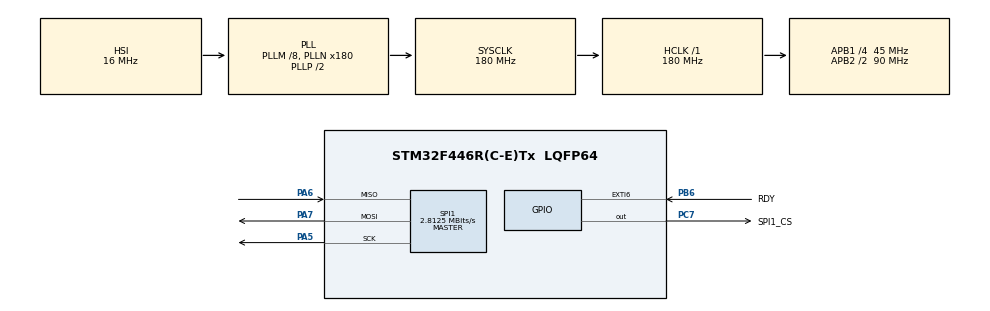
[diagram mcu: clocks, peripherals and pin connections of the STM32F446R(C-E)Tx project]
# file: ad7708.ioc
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Mcu.Family=STM32F4
Mcu.Name=STM32F446R(C-E)Tx
Mcu.Package=LQFP64
NVIC.PriorityGroup=NVIC_PRIORITYGROUP_4
PA13.Mode=Serial_Wire
PA13.Signal=SYS_JTMS-SWDIO
PA14.Mode=Serial_Wire
PA14.Signal=SYS_JTCK-SWCLK
PA5.Mode=Full_Duplex_Master
PA5.Signal=SPI1_SCK
PA6.Mode=Full_Duplex_Master
PA6.Signal=SPI1_MISO
PA7.Mode=Full_Duplex_Master
PA7.Signal=SPI1_MOSI
PB6.GPIO_Label=RDY
PB6.GPIO_ModeDefaultEXTI=GPIO_MODE_IT_FALLING
PB6.Signal=GPXTI6
PC7.GPIO_Label=SPI1_CS
PC7.Signal=GPIO_Output
PH0-OSC_IN.Mode=HSE-External-Oscillator
PH0-OSC_IN.Signal=RCC_OSC_IN
PH1-OSC_OUT.Mode=HSE-External-Oscillator
PH1-OSC_OUT.Signal=RCC_OSC_OUT
ProjectManager.HeapSize=0x200
ProjectManager.StackSize=0x400
ProjectManager.TargetToolchain=STM32CubeIDE
RCC.AHBFreq_Value=180000000
RCC.APB1CLKDivider=RCC_HCLK_DIV4
RCC.APB1Freq_Value=45000000
RCC.APB1TimFreq_Value=90000000
RCC.APB2CLKDivider=RCC_HCLK_DIV2
RCC.APB2Freq_Value=90000000
RCC.APB2TimFreq_Value=180000000
RCC.CortexFreq_Value=180000000
RCC.HCLKFreq_Value=180000000
RCC.PLLM=8
RCC.PLLN=180
RCC.SYSCLKFreq_VALUE=180000000
RCC.SYSCLKSource=RCC_SYSCLKSOURCE_PLLCLK
RCC.USBFreq_Value=180000000
RCC.VCOOutputFreq_Value=360000000
SPI1.BaudRatePrescaler=SPI_BAUDRATEPRESCALER_32
SPI1.CalculateBaudRate=2.8125 MBits/s
SPI1.Direction=SPI_DIRECTION_2LINES
SPI1.Mode=SPI_MODE_MASTER
SPI1.VirtualType=VM_MASTER
board=custom

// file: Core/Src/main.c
/* USER CODE BEGIN Header */
/**
  ******************************************************************************
  * @file           : main.c
  * @brief          : Main program body
  ******************************************************************************
  * @attention
  *
  * Copyright (c) 2023 STMicroelectronics.
  * All rights reserved.
  *
  * This software is licensed under terms that can be found in the LICENSE file
  * in the root directory of this software component.
  * If no LICENSE file comes with this software, it is provided AS-IS.
  *
  ******************************************************************************
  */
/* USER CODE END Header */
#include "main.h"
#include "spi.h"
#include "gpio.h"

/* USER CODE BEGIN Includes */
#include "ad7708.h"

/* USER CODE END Includes */

/* USER CODE BEGIN PV */
 ad7708_dev ad7708;

/* USER CODE END PV */

void SystemClock_Config(void);

/* USER CODE BEGIN 0 */
void HAL_GPIO_EXTI_Callback(uint16_t GPIO_Pin){
	if(GPIO_Pin == AD7708_RDY_Pin){
		//Reading data from adc

	}

}
/* USER CODE END 0 */

int main(void)
{
  /* USER CODE BEGIN 1 */
  ad7708_init(&ad7708);
  ad7708_areYouThere(&ad7708);

  /* USER CODE END 1 */

  /* MCU Configuration--------------------------------------------------------*/

  /* Reset of all peripherals, Initializes the Flash interface and the Systick. */
  HAL_Init();

  /* Configure the system clock */
  SystemClock_Config();

  /* Initialize all configured peripherals */
  MX_GPIO_Init();
  MX_SPI1_Init();

  /* Infinite loop */
  while (1)
  {

  }
}

void SystemClock_Config(void)
{
  RCC_OscInitTypeDef RCC_OscInitStruct = {0};
  RCC_ClkInitTypeDef RCC_ClkInitStruct = {0};

  /** Configure the main internal regulator output voltage
  */
  __HAL_RCC_PWR_CLK_ENABLE();
  __HAL_PWR_VOLTAGESCALING_CONFIG(PWR_REGULATOR_VOLTAGE_SCALE1);

  /** Initializes the RCC Oscillators according to the specified parameters
  * in the RCC_OscInitTypeDef structure.
  */
  RCC_OscInitStruct.OscillatorType = RCC_OSCILLATORTYPE_HSI;
  RCC_OscInitStruct.HSIState = RCC_HSI_ON;
  RCC_OscInitStruct.HSICalibrationValue = RCC_HSICALIBRATION_DEFAULT;
  RCC_OscInitStruct.PLL.PLLState = RCC_PLL_ON;
  RCC_OscInitStruct.PLL.PLLSource = RCC_PLLSOURCE_HSI;
  RCC_OscInitStruct.PLL.PLLM = 8;
  RCC_OscInitStruct.PLL.PLLN = 180;
  RCC_OscInitStruct.PLL.PLLP = RCC_PLLP_DIV2;
  RCC_OscInitStruct.PLL.PLLQ = 2;
  RCC_OscInitStruct.PLL.PLLR = 2;
  if (HAL_RCC_OscConfig(&RCC_OscInitStruct) != HAL_OK)
  {
    Error_Handler();
  }

  /** Activate the Over-Drive mode
  */
  if (HAL_PWREx_EnableOverDrive() != HAL_OK)
  {
    Error_Handler();
  }

  /** Initializes the CPU, AHB and APB buses clocks
  */
  RCC_ClkInitStruct.ClockType = RCC_CLOCKTYPE_HCLK|RCC_CLOCKTYPE_SYSCLK
                              |RCC_CLOCKTYPE_PCLK1|RCC_CLOCKTYPE_PCLK2;
  RCC_ClkInitStruct.SYSCLKSource = RCC_SYSCLKSOURCE_PLLCLK;
  RCC_ClkInitStruct.AHBCLKDivider = RCC_SYSCLK_DIV1;
  RCC_ClkInitStruct.APB1CLKDivider = RCC_HCLK_DIV4;
  RCC_ClkInitStruct.APB2CLKDivider = RCC_HCLK_DIV2;

  if (HAL_RCC_ClockConfig(&RCC_ClkInitStruct, FLASH_LATENCY_5) != HAL_OK)
  {
    Error_Handler();
  }
}

void Error_Handler(void)
{
  __disable_irq();
  while (1)
  {
  }
}
